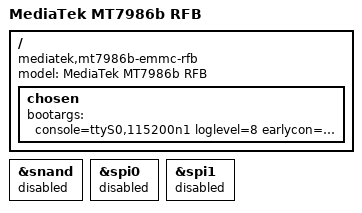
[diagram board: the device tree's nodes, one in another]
/dts-v1/;
#include "mt7986b-rfb.dtsi"
/ {
	model = "MediaTek MT7986b RFB";
	compatible = "mediatek,mt7986b-emmc-rfb";

	chosen {
		bootargs = "console=ttyS0,115200n1 loglevel=8  \
				earlycon=uart8250,mmio32,0x11002000 \
				root=/dev/mmcblk0p7 rootwait rootfstype=squashfs,f2fs";
	};
};

&snand {
	status = "disabled";
};

&spi0 {
	status = "disabled";
};

&spi1 {
	status = "disabled";
};
